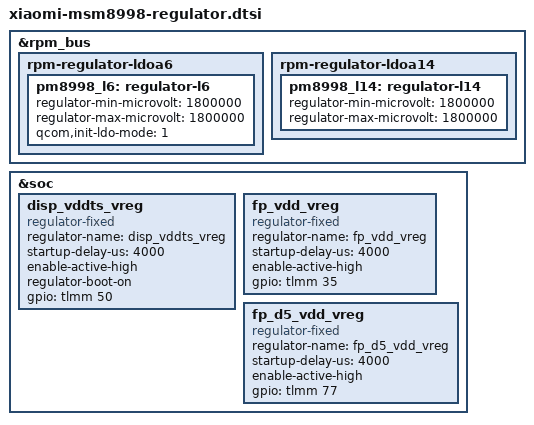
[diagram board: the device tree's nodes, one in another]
/* Copyright (c) 2015-2017, The Linux Foundation. All rights reserved.
 * Copyright (C) 2017 XiaoMi, Inc.
 *
 * This program is free software; you can redistribute it and/or modify
 * it under the terms of the GNU General Public License version 2 and
 * only version 2 as published by the Free Software Foundation.
 *
 * This program is distributed in the hope that it will be useful,
 * but WITHOUT ANY WARRANTY; without even the implied warranty of
 * MERCHANTABILITY or FITNESS FOR A PARTICULAR PURPOSE.  See the
 * GNU General Public License for more details.
 */

&rpm_bus {
	rpm-regulator-ldoa6 {
		pm8998_l6: regulator-l6 {
			regulator-min-microvolt = <1800000>;
			regulator-max-microvolt = <1800000>;
			qcom,init-ldo-mode = <1>;
		};
	};

	rpm-regulator-ldoa14 {
		pm8998_l14: regulator-l14 {
			regulator-min-microvolt = <1800000>;
			regulator-max-microvolt = <1800000>;
		};
	};
};

&soc {
	disp_vddts_vreg: disp_vddts_vreg {
		compatible = "regulator-fixed";
		regulator-name = "disp_vddts_vreg";
		startup-delay-us = <4000>;
		enable-active-high;
		regulator-boot-on;
		gpio = <&tlmm 50 0>;
	};

	fp_vdd_vreg: fp_vdd_vreg {
		compatible = "regulator-fixed";
		regulator-name = "fp_vdd_vreg";
		startup-delay-us = <4000>;
		enable-active-high;
		gpio = <&tlmm 35 0>;
	};

	fp_d5_vdd_vreg: fp_d5_vdd_vreg {
		compatible = "regulator-fixed";
		regulator-name = "fp_d5_vdd_vreg";
		startup-delay-us = <4000>;
		enable-active-high;
		gpio = <&tlmm 77 0>;
	};
};
